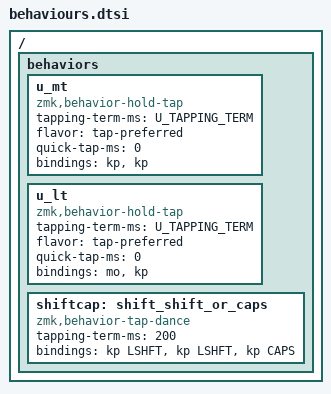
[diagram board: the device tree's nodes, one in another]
/ {
    behaviors {
        u_mt: u_mt {
            compatible = "zmk,behavior-hold-tap";
            #binding-cells = <2>;
            tapping-term-ms = <U_TAPPING_TERM>;
            flavor = "tap-preferred";
            quick-tap-ms = <0>;
            bindings = <&kp>, <&kp>;
        };

        u_lt: u_lt {
            compatible = "zmk,behavior-hold-tap";
            #binding-cells = <2>;
            tapping-term-ms = <U_TAPPING_TERM>;
            flavor = "tap-preferred";
            quick-tap-ms = <0>;
            bindings = <&mo>, <&kp>;
        };
        
        // Hold: LSHFT
        // CAPS is activated by tapping shift key trice
        shiftcap: shift_shift_or_caps {
            compatible = "zmk,behavior-tap-dance";
            #binding-cells = <0>;
            tapping-term-ms = <200>;
            bindings = <&kp LSHFT>, <&kp LSHFT>, <&kp CAPS>;
        };
  };
};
